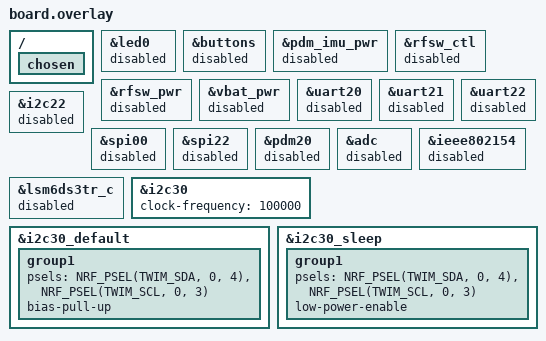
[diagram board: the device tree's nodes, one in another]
#include <zephyr/dt-bindings/gpio/gpio.h>
#include <zephyr/dt-bindings/pinctrl/nrf-pinctrl.h>

/ {
 chosen {
  /delete-property/ zephyr,console;
  /delete-property/ zephyr,shell-uart;
  /delete-property/ nordic,rpc-uart;
  /delete-property/ zephyr,ieee802154;
 };
};
/* P2.00/P2.05 are carrier power/LED, not the stock XIAO functions. */
&led0 { status = "disabled"; };
&buttons { status = "disabled"; };
&pdm_imu_pwr { status = "disabled"; };
&rfsw_ctl { status = "disabled"; };
&rfsw_pwr { status = "disabled"; };
&vbat_pwr { status = "disabled"; };
/delete-node/ &imu_power_default_on;
&uart20 { status = "disabled"; };
&uart21 { status = "disabled"; };
&uart22 { status = "disabled"; };
&i2c22 { status = "disabled"; };
&spi00 { status = "disabled"; };
&spi22 { status = "disabled"; };
&pdm20 { status = "disabled"; };
&adc { status = "disabled"; };
&ieee802154 { status = "disabled"; };
&lsm6ds3tr_c { status = "disabled"; };
/* IMU is permanently powered on this carrier. Briefly use I2C to shut it
 * down, including after a warm reset that left motion wake enabled. */
&i2c30 { status = "okay"; clock-frequency = <100000>; };
&i2c30_default {
 group1 {
  psels = <NRF_PSEL(TWIM_SDA, 0, 4)>, <NRF_PSEL(TWIM_SCL, 0, 3)>;
  bias-pull-up;
 };
};
&i2c30_sleep {
 group1 {
  psels = <NRF_PSEL(TWIM_SDA, 0, 4)>, <NRF_PSEL(TWIM_SCL, 0, 3)>;
  low-power-enable;
 };
};
